VERSION ""

NS_ :

BS_: 500

BU_: Vector__XXX

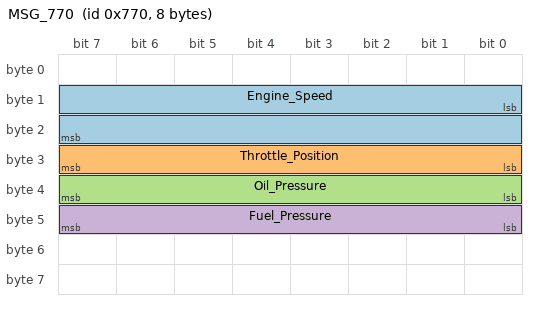
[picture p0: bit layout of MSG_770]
BO_ 1904 MSG_770: 8 Vector__XXX
 SG_ Engine_Speed : 8|16@1+ (0.25,0) [0|10000] "rpm" Vector__XXX
 SG_ Throttle_Position : 24|8@1+ (0.47,0) [0|0] "%" Vector__XXX
 SG_ Oil_Pressure : 32|8@1+ (6.27,0) [0|0] "kPa" Vector__XXX
 SG_ Fuel_Pressure : 40|8@1+ (6.27,0) [0|0] "kPa" Vector__XXX

BO_ 1905 MSG_771: 8 Vector__XXX
 SG_ Wheel_Speed_1_kph : 8|16@1+ (0.78,0) [0|0] "km/h" Vector__XXX
 SG_ Wheel_Speed_1_mph : 8|16@1+ (0.48438,0) [0|0] "mph" Vector__XXX
